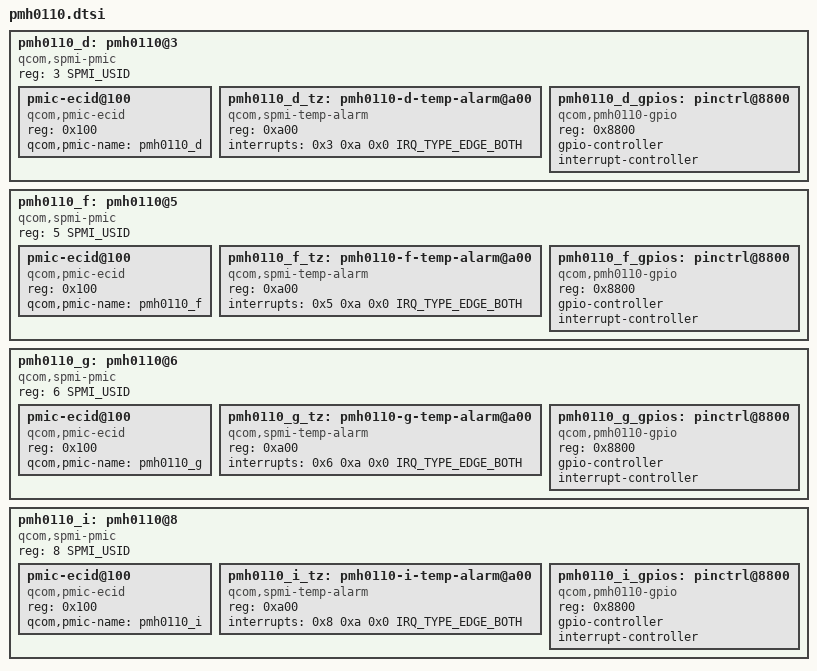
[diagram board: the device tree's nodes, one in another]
// SPDX-License-Identifier: BSD-3-Clause
/*
 * Copyright (c) 2024-2025 Qualcomm Innovation Center, Inc. All rights reserved.
 */

#include <dt-bindings/interrupt-controller/irq.h>
#include <dt-bindings/spmi/spmi.h>

pmh0110_d: pmh0110@3 {
	compatible = "qcom,spmi-pmic";
	reg = <3 SPMI_USID>;
	#address-cells = <1>;
	#size-cells = <0>;

	pmic-ecid@100 {
		compatible = "qcom,pmic-ecid";
		reg = <0x100>;
		qcom,pmic-name = "pmh0110_d";
	};

	pmh0110_d_tz: pmh0110-d-temp-alarm@a00 {
		compatible = "qcom,spmi-temp-alarm";
		reg = <0xa00>;
		interrupts = <0x3 0xa 0x0 IRQ_TYPE_EDGE_BOTH>;
		#thermal-sensor-cells = <0>;
	};

	pmh0110_d_gpios: pinctrl@8800 {
		compatible = "qcom,pmh0110-gpio";
		reg = <0x8800>;
		gpio-controller;
		#gpio-cells = <2>;
		interrupt-controller;
		#interrupt-cells = <2>;
	};
};

pmh0110_f: pmh0110@5 {
	compatible = "qcom,spmi-pmic";
	reg = <5 SPMI_USID>;
	#address-cells = <1>;
	#size-cells = <0>;

	pmic-ecid@100 {
		compatible = "qcom,pmic-ecid";
		reg = <0x100>;
		qcom,pmic-name = "pmh0110_f";
	};

	pmh0110_f_tz: pmh0110-f-temp-alarm@a00 {
		compatible = "qcom,spmi-temp-alarm";
		reg = <0xa00>;
		interrupts = <0x5 0xa 0x0 IRQ_TYPE_EDGE_BOTH>;
		#thermal-sensor-cells = <0>;
	};

	pmh0110_f_gpios: pinctrl@8800 {
		compatible = "qcom,pmh0110-gpio";
		reg = <0x8800>;
		gpio-controller;
		#gpio-cells = <2>;
		interrupt-controller;
		#interrupt-cells = <2>;
	};
};

pmh0110_g: pmh0110@6 {
	compatible = "qcom,spmi-pmic";
	reg = <6 SPMI_USID>;
	#address-cells = <1>;
	#size-cells = <0>;

	pmic-ecid@100 {
		compatible = "qcom,pmic-ecid";
		reg = <0x100>;
		qcom,pmic-name = "pmh0110_g";
	};

	pmh0110_g_tz: pmh0110-g-temp-alarm@a00 {
		compatible = "qcom,spmi-temp-alarm";
		reg = <0xa00>;
		interrupts = <0x6 0xa 0x0 IRQ_TYPE_EDGE_BOTH>;
		#thermal-sensor-cells = <0>;
	};

	pmh0110_g_gpios: pinctrl@8800 {
		compatible = "qcom,pmh0110-gpio";
		reg = <0x8800>;
		gpio-controller;
		#gpio-cells = <2>;
		interrupt-controller;
		#interrupt-cells = <2>;
	};
};

pmh0110_i: pmh0110@8 {
	compatible = "qcom,spmi-pmic";
	reg = <8 SPMI_USID>;
	#address-cells = <1>;
	#size-cells = <0>;

	pmic-ecid@100 {
		compatible = "qcom,pmic-ecid";
		reg = <0x100>;
		qcom,pmic-name = "pmh0110_i";
	};

	pmh0110_i_tz: pmh0110-i-temp-alarm@a00 {
		compatible = "qcom,spmi-temp-alarm";
		reg = <0xa00>;
		interrupts = <0x8 0xa 0x0 IRQ_TYPE_EDGE_BOTH>;
		#thermal-sensor-cells = <0>;
	};

	pmh0110_i_gpios: pinctrl@8800 {
		compatible = "qcom,pmh0110-gpio";
		reg = <0x8800>;
		gpio-controller;
		#gpio-cells = <2>;
		interrupt-controller;
		#interrupt-cells = <2>;
	};
};
